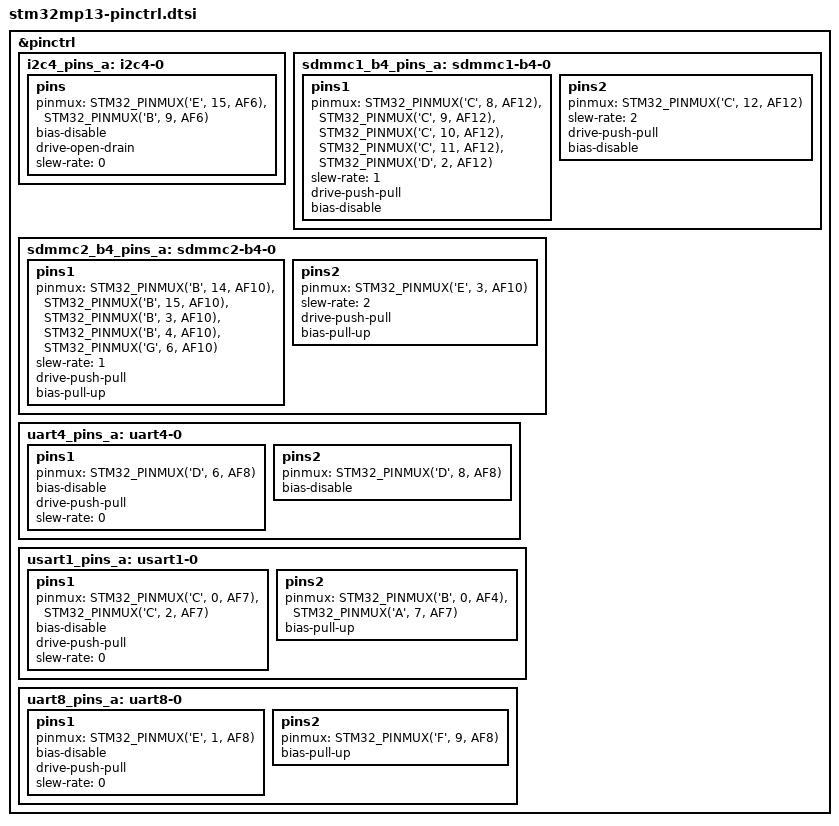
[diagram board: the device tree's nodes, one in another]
// SPDX-License-Identifier: (GPL-2.0+ OR BSD-3-Clause)
/*
 * Copyright (C) STMicroelectronics 2022 - All Rights Reserved
 * Author: Alexandre Torgue <alexandre.torgue@foss.st.com>
 */
#include <dt-bindings/pinctrl/stm32-pinfunc.h>

&pinctrl {
	i2c4_pins_a: i2c4-0 {
		pins {
			pinmux = <STM32_PINMUX('E', 15, AF6)>, /* I2C4_SCL */
				 <STM32_PINMUX('B', 9, AF6)>; /* I2C4_SDA */
			bias-disable;
			drive-open-drain;
			slew-rate = <0>;
		};
	};

	sdmmc1_b4_pins_a: sdmmc1-b4-0 {
		pins1 {
			pinmux = <STM32_PINMUX('C', 8, AF12)>, /* SDMMC1_D0 */
				 <STM32_PINMUX('C', 9, AF12)>, /* SDMMC1_D1 */
				 <STM32_PINMUX('C', 10, AF12)>, /* SDMMC1_D2 */
				 <STM32_PINMUX('C', 11, AF12)>, /* SDMMC1_D3 */
				 <STM32_PINMUX('D', 2, AF12)>; /* SDMMC1_CMD */
			slew-rate = <1>;
			drive-push-pull;
			bias-disable;
		};
		pins2 {
			pinmux = <STM32_PINMUX('C', 12, AF12)>; /* SDMMC1_CK */
			slew-rate = <2>;
			drive-push-pull;
			bias-disable;
		};
	};

	sdmmc2_b4_pins_a: sdmmc2-b4-0 {
		pins1 {
			pinmux = <STM32_PINMUX('B', 14, AF10)>, /* SDMMC2_D0 */
				 <STM32_PINMUX('B', 15, AF10)>, /* SDMMC2_D1 */
				 <STM32_PINMUX('B', 3, AF10)>, /* SDMMC2_D2 */
				 <STM32_PINMUX('B', 4, AF10)>, /* SDMMC2_D3 */
				 <STM32_PINMUX('G', 6, AF10)>; /* SDMMC2_CMD */
			slew-rate = <1>;
			drive-push-pull;
			bias-pull-up;
		};
		pins2 {
			pinmux = <STM32_PINMUX('E', 3, AF10)>; /* SDMMC2_CK */
			slew-rate = <2>;
			drive-push-pull;
			bias-pull-up;
		};
	};

	uart4_pins_a: uart4-0 {
		pins1 {
			pinmux = <STM32_PINMUX('D', 6, AF8)>; /* UART4_TX */
			bias-disable;
			drive-push-pull;
			slew-rate = <0>;
		};
		pins2 {
			pinmux = <STM32_PINMUX('D', 8, AF8)>; /* UART4_RX */
			bias-disable;
		};
	};

	usart1_pins_a: usart1-0 {
		pins1 {
			pinmux = <STM32_PINMUX('C', 0, AF7)>, /* USART1_TX */
				 <STM32_PINMUX('C', 2, AF7)>; /* USART1_RTS */
			bias-disable;
			drive-push-pull;
			slew-rate = <0>;
		};
		pins2 {
			pinmux = <STM32_PINMUX('B', 0, AF4)>, /* USART1_RX */
				 <STM32_PINMUX('A', 7, AF7)>; /* USART1_CTS_NSS */
			bias-pull-up;
		};
	};

	uart8_pins_a: uart8-0 {
		pins1 {
			pinmux = <STM32_PINMUX('E', 1, AF8)>; /* UART8_TX */
			bias-disable;
			drive-push-pull;
			slew-rate = <0>;
		};
		pins2 {
			pinmux = <STM32_PINMUX('F', 9, AF8)>; /* UART8_RX */
			bias-pull-up;
		};
	};
};
